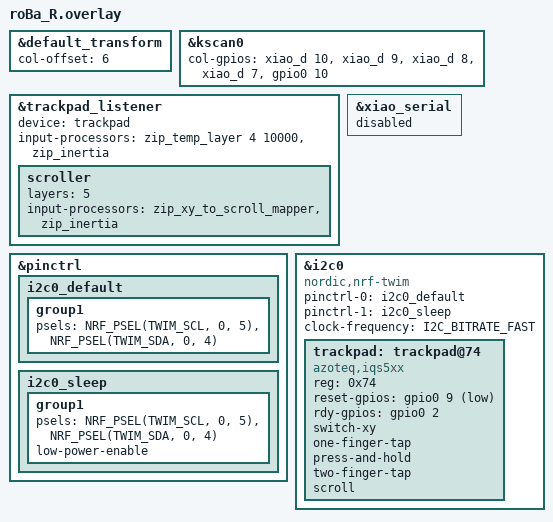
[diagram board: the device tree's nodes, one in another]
#include "roBa.dtsi"
#include <zephyr/dt-bindings/i2c/i2c.h>
#include <input/processors.dtsi>
#include <zmk-input-inertia/input/processor/input_inertia.dtsi>

&default_transform {
    col-offset = <6>;
};

&kscan0 {
        col-gpios
            = <&xiao_d 10 GPIO_ACTIVE_HIGH>
            , <&xiao_d 9 GPIO_ACTIVE_HIGH>
            , <&xiao_d 8 GPIO_ACTIVE_HIGH>
            , <&xiao_d 7 GPIO_ACTIVE_HIGH>
            , <&gpio0 10 GPIO_ACTIVE_HIGH>
            ;
};

/* zip_inertia auto-detects move (REL_X/REL_Y) vs scroll (REL_WHEEL/REL_HWHEEL)
 * events by code and applies its own move- and scroll- thresholds to each, so
 * one shared instance below covers both the plain cursor movement + native
 * two-finger scroll gesture (base chain) and the SCROLL-layer-mapped scroll
 * (layer override) - referencing the same node in both places (as the module
 * requires) lets it also detect "moved the cursor while coasting a scroll"
 * and stop cleanly. Left at module defaults for now (module's own defaults
 * already assume small per-report deltas, unlike the previous module). This
 * node must stay on the R (central) side only - the module's Kconfig refuses
 * to build it on a peripheral. */

&trackpad_listener {
    status = "okay";
    device = <&trackpad>;
    input-processors = <&zip_temp_layer 4 10000 &zip_inertia>;

    /* While the SCROLL layer (5) is held, map the trackpad's single-finger raw
     * movement to wheel/hwheel events instead of cursor movement, then add
     * inertia to that. This restores the old trackball's `scroll-layers = <5>`
     * behavior, which the IQS5xx driver has no equivalent devicetree property
     * for - so it's rebuilt here as a layer-specific input-processor override. */
    scroller {
        layers = <5>;
        input-processors = <&zip_xy_to_scroll_mapper &zip_inertia>;
    };
};

/* i2c0 and spi0 are the same nRF52840 peripheral instance (0x40003000) -
 * only one may be enabled at a time. The trackball's SPI0 pins (P0.05,
 * P0.04) are reused here as I2C0 SCL/SDA since SPI0 is no longer used. */
&pinctrl {
    i2c0_default: i2c0_default {
        group1 {
            psels = <NRF_PSEL(TWIM_SCL, 0, 5)>,
                <NRF_PSEL(TWIM_SDA, 0, 4)>;
        };
    };

    i2c0_sleep: i2c0_sleep {
        group1 {
            psels = <NRF_PSEL(TWIM_SCL, 0, 5)>,
                <NRF_PSEL(TWIM_SDA, 0, 4)>;
            low-power-enable;
        };
    };
};

&xiao_serial { status = "disabled"; };

&i2c0 {
    status = "okay";
    compatible = "nordic,nrf-twim";
    pinctrl-0 = <&i2c0_default>;
    pinctrl-1 = <&i2c0_sleep>;
    pinctrl-names = "default", "sleep";
    clock-frequency = <I2C_BITRATE_FAST>;

    /* TPS43 (Azoteq IQS572) trackpad, I2C mode - the module's only interface.
     * reg 0x74 is the IQS5xx family's fixed 7-bit I2C address.
     * TODO: reset-gpios/rdy-gpios reuse the trackball's old CS (P0.09) and
     * IRQ (P0.02) pins as placeholders - confirm against the actual TPS43
     * FFC wiring (J1: 1=RDY, 2=SDA, 3=GND, 4=VDDHI, 5=SCL, 6=NRST). */
    trackpad: trackpad@74 {
        status = "okay";
        compatible = "azoteq,iqs5xx";
        reg = <0x74>;
        reset-gpios = <&gpio0 9 GPIO_ACTIVE_LOW>;
        rdy-gpios = <&gpio0 2 GPIO_ACTIVE_HIGH>;

        /* Sensor's raw axes are rotated 90 degrees from the module's mounted
         * orientation (physically rotating the pad 90 deg clockwise fixes it) -
         * compensate in software instead by swapping x/y. */
        switch-xy;

        one-finger-tap;
        press-and-hold;
        two-finger-tap;
        scroll;
    };
};
